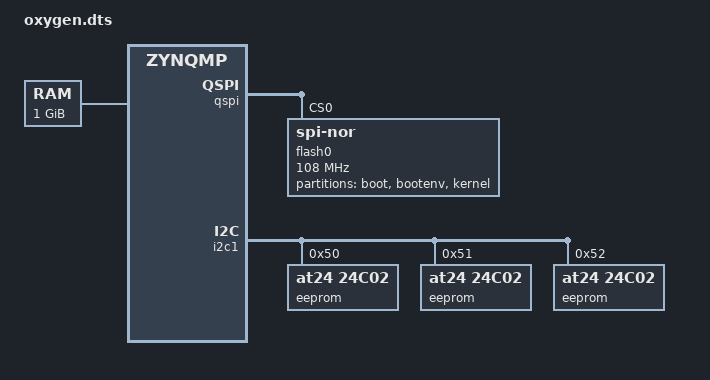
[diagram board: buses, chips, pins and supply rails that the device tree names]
/*
 * CAUTION: This file is automatically generated by Xilinx.
 * Version:
 * Today is: Fri Apr  6 17:23:13 2018
 */


/dts-v1/;
#include "zynqmp.dtsi"
#include "zynqmp-clk-ccf.dtsi"
#include "oxygen-pcw.dtsi"
#include <dt-bindings/interrupt-controller/irq.h>
#include <dt-bindings/pinctrl/pinctrl-zynqmp.h>
#include <dt-bindings/phy/phy.h>
#include <dt-bindings/input/input.h>
#include <dt-bindings/gpio/gpio.h>

/ {
    chosen {
        bootargs = "earlycon clk_ignore_unused root=/dev/mmcblk1p2 rw rootwait";
        stdout-path = "serial0:115200n8";
    };

    aliases {
        serial0 = &uart0;
        serial1 = &uart1;
        spi0 = &qspi;
        spi1 = &spi0;
    };
    memory {
        device_type = "memory";
        reg = <0x0 0x0 0x0 0x40000000>;
    };

    clocks: clocks {
            ad9361_clkin: clock@0 {
                #clock-cells = <0>;
                compatible = "adjustable-clock";
                clock-frequency = <40000000>;
                clock-accuracy = <200000>; /* 200 ppm (ppb) */
                clock-output-names = "ad9361_ext_refclk";
            };
    };

    fpga_axi: fpga-axi@0 {
        interrupt-parent = <&gic>;
        compatible = "simple-bus";
        #address-cells = <0x1>;
        #size-cells = <0x1>;
        ranges = <0 0 0 0xffffffff>;

    };

};


&qspi {
    #address-cells = <1>;
    #size-cells = <0>;
    flash0: flash@0 {
        compatible = "n25q512a","micron,m25p80";
        spi-tx-bus-width=<1>;
        spi-rx-bus-width=<4>;
        reg = <0x0>;
        #address-cells = <1>;
        #size-cells = <1>;
        spi-max-frequency = <108000000>;
        partition@0x00000000 {
            label = "boot";
            reg = <0x00000000 0x00100000>;
        };
        partition@0x00100000 {
            label = "bootenv";
            reg = <0x00100000 0x00040000>;
        };
        partition@0x00140000 {
            label = "kernel";
            reg = <0x00140000 0x01600000>;
        };
    };
};


/* SDIO */

&sdhci1 {
   disable-wp;
   no-1-8-v;
   /* broken-adma2; */
};

/* QSPI PHY */
&qspi {
    #address-cells = <1>;
    #size-cells = <0>;
    flash0: flash@0 {
         compatible = "jedec,spi-nor";
        reg = <0x0>;
        #address-cells = <1>;
        #size-cells = <1>;
    };
};


/* DMA not used: Reduce error messages on linux.*/

&lpd_dma_chan1 {
    status = "disabled";
};
&lpd_dma_chan2 {
    status = "disabled";
};
&lpd_dma_chan3 {
    status = "disabled";
};
&lpd_dma_chan4 {
    status = "disabled";
};
&lpd_dma_chan5 {
    status = "disabled";
};
&lpd_dma_chan6 {
    status = "disabled";
};
&lpd_dma_chan7 {
    status = "disabled";
};
&lpd_dma_chan8 {
    status = "disabled";
};


&usb0 {
	status = "disabled";
};

&dwc3_0 {
    status = "disabled";
    dr_mode = "peripheral";
    maximum-speed = "super-speed";
    snps,usb3_lpm_capable;
    phy-names = "usb3-phy";
    phys = <&lane2 4 0 3 100000000>;
};

&i2c1 {
    eeprom@50 {
      compatible = "at24,24c02";
      reg = <0x50>;
    };
    eeprom@51 {
      compatible = "at24,24c02";
      reg = <0x51>;
    };
    eeprom@52 {
      compatible = "at24,24c02";
      reg = <0x52>;
    };

    
};
